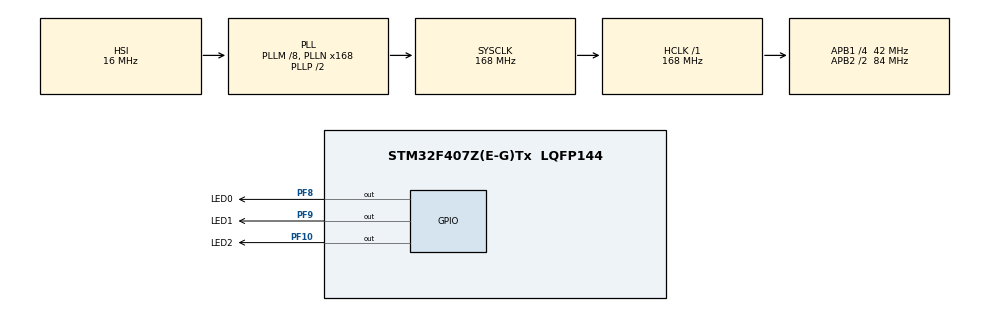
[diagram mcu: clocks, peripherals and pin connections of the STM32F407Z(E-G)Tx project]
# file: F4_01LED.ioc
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Mcu.Family=STM32F4
PH0-OSC_IN.Signal=RCC_OSC_IN
PF10.GPIO_ModeDefaultOutputPP=GPIO_MODE_OUTPUT_PP
RCC.CortexFreq_Value=168000000
PF10.GPIO_Speed=GPIO_SPEED_FREQ_VERY_HIGH
PF9.GPIO_Speed=GPIO_SPEED_FREQ_VERY_HIGH
RCC.APB1CLKDivider=RCC_HCLK_DIV4
PF10.GPIO_PuPd=GPIO_PULLUP
PF8.PinState=GPIO_PIN_SET
RCC.SYSCLKSource=RCC_SYSCLKSOURCE_PLLCLK
ProjectManager.StackSize=0x400
PF8.GPIO_Label=LED0
PA13.Signal=SYS_JTMS-SWDIO
ProjectManager.TargetToolchain=STM32CubeIDE
PF9.PinState=GPIO_PIN_SET
RCC.HCLKFreq_Value=168000000
RCC.APB2TimFreq_Value=168000000
PF9.GPIO_Label=LED1
RCC.LSE_VALUE=32768
PF10.GPIO_Label=LED2
RCC.AHBFreq_Value=168000000
PH0-OSC_IN.Mode=HSE-External-Oscillator
RCC.HSE_VALUE=8000000
board=custom
RCC.VCOOutputFreq_Value=336000000
RCC.APB2Freq_Value=84000000
PF8.GPIO_ModeDefaultOutputPP=GPIO_MODE_OUTPUT_PP
PF8.GPIO_PuPd=GPIO_PULLUP
PA14.Mode=Serial_Wire
PF10.Signal=GPIO_Output
PH1-OSC_OUT.Signal=RCC_OSC_OUT
PA13.Mode=Serial_Wire
Mcu.Name=STM32F407Z(E-G)Tx
PH1-OSC_OUT.Mode=HSE-External-Oscillator
RCC.48MHZClocksFreq_Value=84000000
RCC.SYSCLKFreq_VALUE=168000000
Mcu.Package=LQFP144
PA14.Signal=SYS_JTCK-SWCLK
ProjectManager.HeapSize=0x200
PF8.Signal=GPIO_Output
PF9.Signal=GPIO_Output
RCC.HSI_VALUE=16000000
PF9.GPIO_ModeDefaultOutputPP=GPIO_MODE_OUTPUT_PP
NVIC.PriorityGroup=NVIC_PRIORITYGROUP_4
RCC.APB2CLKDivider=RCC_HCLK_DIV2
RCC.PLLM=8
RCC.PLLN=168
PF8.GPIO_Speed=GPIO_SPEED_FREQ_VERY_HIGH
RCC.APB1TimFreq_Value=84000000
PF9.GPIO_PuPd=GPIO_PULLUP
RCC.APB1Freq_Value=42000000
PF10.PinState=GPIO_PIN_SET

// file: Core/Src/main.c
/* USER CODE BEGIN Header */
/**
  ******************************************************************************
  * @file           : main.c
  * @brief          : Main program body
  ******************************************************************************
  * @attention
  *
  * <h2><center>&copy; Copyright (c) 2021 STMicroelectronics.
  * All rights reserved.</center></h2>
  *
  * This software component is licensed by ST under BSD 3-Clause license,
  * the "License"; You may not use this file except in compliance with the
  * License. You may obtain a copy of the License at:
  *                        opensource.org/licenses/BSD-3-Clause
  *
  ******************************************************************************
  */
/* USER CODE END Header */
#include "main.h"
#include "gpio.h"

/* USER CODE BEGIN Includes */
#include "base.h"
/* USER CODE END Includes */

void SystemClock_Config(void);

int main(void)
{

  /* MCU Configuration--------------------------------------------------------*/

  /* Reset of all peripherals, Initializes the Flash interface and the Systick. */
  HAL_Init();

  /* Configure the system clock */
  SystemClock_Config();

  /* Initialize all configured peripherals */
  MX_GPIO_Init();
  /* USER CODE BEGIN 2 */
  delay_init(168);
  /* USER CODE END 2 */

  /* Infinite loop */
  while (1)
  {

    /* USER CODE BEGIN 3 */
	  LED0_T;
	  LED1_T;
	  LED2_T;
	  delay_ms(500);
  }
  /* USER CODE END 3 */
}

void SystemClock_Config(void)
{
  RCC_OscInitTypeDef RCC_OscInitStruct = {0};
  RCC_ClkInitTypeDef RCC_ClkInitStruct = {0};

  /** Configure the main internal regulator output voltage
  */
  __HAL_RCC_PWR_CLK_ENABLE();
  __HAL_PWR_VOLTAGESCALING_CONFIG(PWR_REGULATOR_VOLTAGE_SCALE1);
  /** Initializes the RCC Oscillators according to the specified parameters
  * in the RCC_OscInitTypeDef structure.
  */
  RCC_OscInitStruct.OscillatorType = RCC_OSCILLATORTYPE_HSI;
  RCC_OscInitStruct.HSIState = RCC_HSI_ON;
  RCC_OscInitStruct.HSICalibrationValue = RCC_HSICALIBRATION_DEFAULT;
  RCC_OscInitStruct.PLL.PLLState = RCC_PLL_ON;
  RCC_OscInitStruct.PLL.PLLSource = RCC_PLLSOURCE_HSI;
  RCC_OscInitStruct.PLL.PLLM = 8;
  RCC_OscInitStruct.PLL.PLLN = 168;
  RCC_OscInitStruct.PLL.PLLP = RCC_PLLP_DIV2;
  RCC_OscInitStruct.PLL.PLLQ = 4;
  if (HAL_RCC_OscConfig(&RCC_OscInitStruct) != HAL_OK)
  {
    Error_Handler();
  }
  /** Initializes the CPU, AHB and APB buses clocks
  */
  RCC_ClkInitStruct.ClockType = RCC_CLOCKTYPE_HCLK|RCC_CLOCKTYPE_SYSCLK
                              |RCC_CLOCKTYPE_PCLK1|RCC_CLOCKTYPE_PCLK2;
  RCC_ClkInitStruct.SYSCLKSource = RCC_SYSCLKSOURCE_PLLCLK;
  RCC_ClkInitStruct.AHBCLKDivider = RCC_SYSCLK_DIV1;
  RCC_ClkInitStruct.APB1CLKDivider = RCC_HCLK_DIV4;
  RCC_ClkInitStruct.APB2CLKDivider = RCC_HCLK_DIV2;

  if (HAL_RCC_ClockConfig(&RCC_ClkInitStruct, FLASH_LATENCY_5) != HAL_OK)
  {
    Error_Handler();
  }
}

void Error_Handler(void)
{
  __disable_irq();
  while (1)
  {
  }
}

/************************ (C) COPYRIGHT STMicroelectronics *****END OF FILE****/
